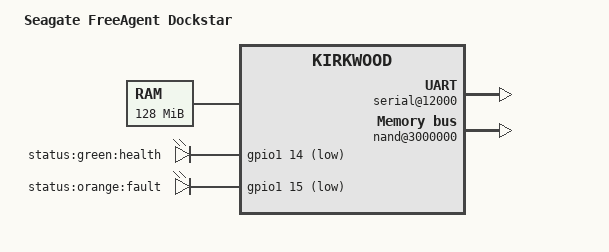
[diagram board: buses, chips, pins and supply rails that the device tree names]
/dts-v1/;

/include/ "kirkwood.dtsi"

/ {
	model = "Seagate FreeAgent Dockstar";
	compatible = "seagate,dockstar", "marvell,kirkwood-88f6281", "marvell,kirkwood";

	memory {
		device_type = "memory";
		reg = <0x00000000 0x8000000>;
	};

	chosen {
		bootargs = "console=ttyS0,115200n8 earlyprintk root=/dev/sda1 rootdelay=10";
	};

	ocp@f1000000 {
		pinctrl: pinctrl@10000 {
			compatible = "marvell,88f6281-pinctrl";
			reg = <0x10000 0x20>;

			pinctrl-0 = < &pmx_usb_power_enable
				      &pmx_led_green &pmx_led_orange >;
			pinctrl-names = "default";

			pmx_usb_power_enable: pmx-usb-power-enable {
				marvell,pins = "mpp29";
				marvell,function = "gpio";
			};
			pmx_led_green: pmx-led-green {
				marvell,pins = "mpp46";
				marvell,function = "gpio";
			};
			pmx_led_orange: pmx-led-orange {
				marvell,pins = "mpp47";
				marvell,function = "gpio";
			};
		};
		serial@12000 {
			clock-frequency = <200000000>;
			status = "ok";
		};

		nand@3000000 {
			status = "okay";

			partition@0 {
				label = "u-boot";
				reg = <0x0000000 0x100000>;
				read-only;
			};

			partition@100000 {
				label = "uImage";
				reg = <0x0100000 0x400000>;
			};

			partition@500000 {
				label = "data";
				reg = <0x0500000 0xfb00000>;
			};
		};
	};
	gpio-leds {
		compatible = "gpio-leds";

		health {
			label = "status:green:health";
			gpios = <&gpio1 14 1>;
			linux,default-trigger = "default-on";
		};
		fault {
			label = "status:orange:fault";
			gpios = <&gpio1 15 1>;
		};
	};
};
